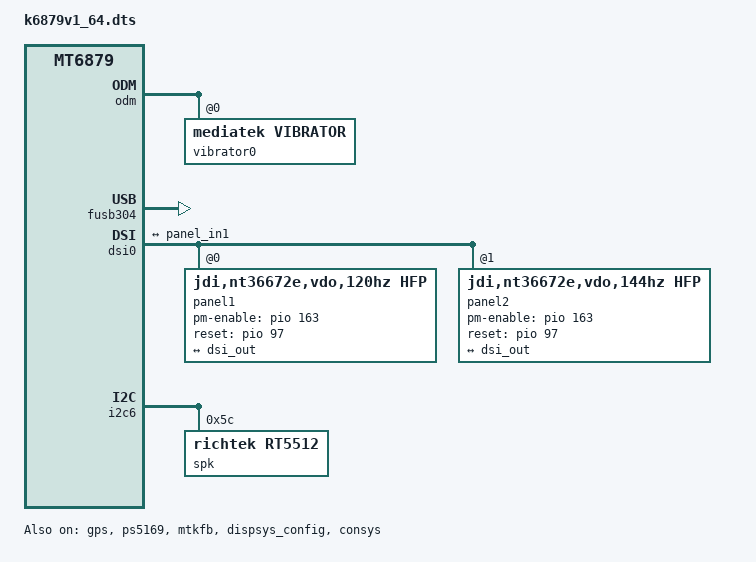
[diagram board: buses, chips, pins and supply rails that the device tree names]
// SPDX-License-Identifier: (GPL-2.0 OR MIT)
/*
 * Copyright (C) 2020 MediaTek Inc.
 * Author: Chun-Hung Wu <chun-hung.wu@mediatek.com>
 */
/dts-v1/;
/plugin/;
#include <dt-bindings/interrupt-controller/arm-gic.h>
#include <dt-bindings/interrupt-controller/irq.h>
#include <dt-bindings/pinctrl/mt6879-pinfunc.h>
#include <dt-bindings/phy/phy.h>
#include <dt-bindings/iio/mt635x-auxadc.h>

&chosen {
	bootargs_ext = "console=tty0 root=/dev/ram \
	androidboot.hardware=mt6879";
};

&mtk_leds {
	compatible = "mediatek,i2c-leds";
	backlight {
		led_mode = <6>;
		gate_enable = <1>;
		pwm_config = <0 1 0 0 0>;
	};
};

&odm {
	vibrator0:vibrator@0 {
		compatible = "mediatek,vibrator";
		vib_timer = <25>;
		vib_limit = <9>;
		vib_vol= <9>;
	};
};

/* GPS GPIO standardization start */
&pio {
	gps_pins_default: gps_default {
	};

	gps_l1_lna_pins_ol: gps_l1_lna@0 {
		pins_cmd_dat {
			pinmux = <PINMUX_GPIO23__FUNC_GPIO23>;
			output-low;
		};
	};
	gps_l1_lna_pins_dsp_ctrl: gps_l1_lna@1 {
		pins_cmd_dat {
			pinmux = <PINMUX_GPIO23__FUNC_GPS_L1_ELNA_EN>;
		};
	};
	gps_l1_lna_pins_oh: gps_l1_lna@2 {
		pins_cmd_dat {
			pinmux = <PINMUX_GPIO23__FUNC_GPIO23>;
			output-high;
		};
	};

	gps_l5_lna_pins_ol: gps_l5_lna@0 {
		pins_cmd_dat {
			pinmux = <PINMUX_GPIO26__FUNC_GPIO26>;
			output-low;
		};
	};
	gps_l5_lna_pins_dsp_ctrl: gps_l5_lna@1 {
		pins_cmd_dat {
			pinmux = <PINMUX_GPIO26__FUNC_GPS_L5_ELNA_EN>;
		};
	};
	gps_l5_lna_pins_oh: gps_l5_lna@2 {
		pins_cmd_dat {
			pinmux = <PINMUX_GPIO26__FUNC_GPIO26>;
			output-high;
		};
	};
};

&gps {
	pinctrl-names = "default",
		"gps_l1_lna_disable",
		"gps_l1_lna_dsp_ctrl",
		"gps_l1_lna_enable",
		"gps_l5_lna_disable",
		"gps_l5_lna_dsp_ctrl",
		"gps_l5_lna_enable";
	pinctrl-0 = <&gps_pins_default>;
	pinctrl-1 = <&gps_l1_lna_pins_ol>;
	pinctrl-2 = <&gps_l1_lna_pins_dsp_ctrl>;
	pinctrl-3 = <&gps_l1_lna_pins_oh>;
	pinctrl-4 = <&gps_l5_lna_pins_ol>;
	pinctrl-5 = <&gps_l5_lna_pins_dsp_ctrl>;
	pinctrl-6 = <&gps_l5_lna_pins_oh>;
	status = "okay";
};
/* GPS GPIO standardization end */

/* usb typec mux start */
&pio {
	sel_up: sel_high {
		pins_cmd_dat {
			pinmux = <PINMUX_GPIO60__FUNC_GPIO60>;
			output-high;
		};
	};

	sel_down: sel_low {
		pins_cmd_dat {
			pinmux = <PINMUX_GPIO60__FUNC_GPIO60>;
			output-low;
		};
	};

	sw_enable: sw_enable {
		pins_cmd_dat {
			pinmux = <PINMUX_GPIO59__FUNC_GPIO59>;
			output-low;
		};
	};

	sw_disable: sw_disable {
		pins_cmd_dat {
			pinmux = <PINMUX_GPIO59__FUNC_GPIO59>;
			output-low;
		};
	};

	ps_enable: ps_enable {
		pins_cmd_dat {
			pinmux = <PINMUX_GPIO136__FUNC_GPIO136>;
			output-high;
		};
	};

	ps_disable: ps_disable {
		pins_cmd_dat {
			pinmux = <PINMUX_GPIO136__FUNC_GPIO136>;
			output-low;
		};
	};
};

&ps5169{
	pinctrl-names = "enable", "disable";
	pinctrl-0 = <&ps_enable>;
	pinctrl-1 = <&ps_disable>;
	status = "okay";
};

&fusb304 {
	pinctrl-names = "sel_up", "sel_down",
		"enable", "disable";
	pinctrl-0 = <&sel_up>;
	pinctrl-1 = <&sel_down>;
	pinctrl-2 = <&sw_enable>;
	pinctrl-3 = <&sw_disable>;
	status = "okay";
};

&mt6375_typec {
	port {
		tcpc_typec_usb: endpoint@0 {
			remote-endpoint = <&ssusb_mux>;
		};
	};
};

&typec_mux_switch {
	orientation-switch;
	mode-switch;
	accessory;
	port {
		ssusb_mux: endpoint@0 {
			remote-endpoint = <&tcpc_typec_usb>;
		};
	};
};

/* usb typec mux end*/

&pio {
	mtkfb_pins_lcm_led_en1: lcm_led_en1_gpio {
		pins_cmd_dat {
			pinmux = <PINMUX_GPIO163__FUNC_GPIO163>;
			slew-rate = <1>;
			output-high;
		};
	};

	mtkfb_pins_lcm_led_en0: lcm_led_en0_gpio {
		pins_cmd_dat {
			pinmux = <PINMUX_GPIO163__FUNC_GPIO163>;
			slew-rate = <1>;
			output-low;
		};
	};

	mtkfb_pins_lcm_rst_out1_gpio: lcm_rst_out1_gpio {
		pins_cmd_dat {
			pinmux = <PINMUX_GPIO97__FUNC_GPIO97>;
			slew-rate = <1>;
			output-high;
		};
	};

	mtkfb_pins_lcm_rst_out0_gpio: lcm_rst_out0_gpio {
		pins_cmd_dat {
			pinmux = <PINMUX_GPIO97__FUNC_GPIO97>;
			slew-rate = <1>;
			output-low;
		};
	};

	mtkfb_pins_lcm_dsi_te: lcm_dsi_te {
		pins_cmd_dat {
			pinmux = <PINMUX_GPIO96__FUNC_DSI_TE>;
		};
	};
};

&mtkfb {
	pinctrl-names = "lcm_led_en1_gpio", "lcm_led_en0_gpio",
		"lcm_rst_out1_gpio", "lcm_rst_out0_gpio",
		"mode_te_te";
	pinctrl-0 = <&mtkfb_pins_lcm_led_en1>;
	pinctrl-1 = <&mtkfb_pins_lcm_led_en0>;
	pinctrl-2 = <&mtkfb_pins_lcm_rst_out1_gpio>;
	pinctrl-3 = <&mtkfb_pins_lcm_rst_out0_gpio>;
	pinctrl-4 = <&mtkfb_pins_lcm_dsi_te>;
	status = "okay";
};

&dispsys_config {
	pinctrl-names =
		"lcm_rst_out1_gpio", "lcm_rst_out0_gpio",
		"mode_te_te";
	pinctrl-0 = <&mtkfb_pins_lcm_rst_out1_gpio>;
	pinctrl-1 = <&mtkfb_pins_lcm_rst_out0_gpio>;
	pinctrl-2 = <&mtkfb_pins_lcm_dsi_te>;
	status = "okay";
};

&dsi0 {
	status = "okay";
	#address-cells = <1>;
	#size-cells = <0>;
	switch_fps = <144>;
	panel1@0 {
		compatible = "jdi,nt36672e,vdo,120hz,hfp";
		reg = <0>;
		pm-enable-gpios = <&pio 163 0>;
		reset-gpios = <&pio 97 0>;
		gate-ic = <4831>;
		pinctrl-names = "default";
		port {
			panel_in1: endpoint {
				remote-endpoint = <&dsi_out>;
			};
		};
	};

	panel2@0 {
		compatible = "jdi,nt36672e,vdo,144hz,hfp";
		reg = <1>;
		pm-enable-gpios = <&pio 163 0>;
		reset-gpios = <&pio 97 0>;
		gate-ic = <4831>;
		pinctrl-names = "default";
		port {
			panel_in2: endpoint {
				remote-endpoint = <&dsi_out>;
			};
		};
	};

	ports {
		port {
			dsi_out: endpoint {
				remote-endpoint = <&panel_in1>;
			};
		};
	};
};

&connfem {
#if 0 /* Enable epa_elna node to support Wifi & BT ePA/eLNA FEM on customer load */
	epa_elna {
		parts = <&qm42195 &qm45197>;

		wifi {
			flags-0 {
				open-loop;
			};
		};

		bt {
			flags-0 {
				/* choose one of: epa_elna / epa / elna / bypass */
				epa_elna;
			};
		};
	};
#endif

	epa_elna_mtk {
		parts = <&nofem &nofem>,		/* [0]iPA/iLNA */
			<&qm42195 &qm45197>,		/* [1]ePA/eLNA - close Loop */
			<&nofem &wlan3002c_laa>,	/* [2]2.4G iPA/iLNA, 5G iPA/eLNA, LAA 4x4 */
			<&qm42195 &qm45197_laa>,	/* [3]ePA/eLNA - close Loop, LAA 4x4 */
			<&qm42195 &qm45197>,		/* [4]ePA/eLNA - open Loop */
			<&qm42195 &qm45197>,		/* [5]ePA/eLNA - close Loop + BT Bypass */
			<&qm42195 &qm45197>,		/* [6]ePA/eLNA - open Loop + BT Bypass */
			<&wlan7207h &wlan7205c>,	/* [7]ePA/eLNA - close Loop */
			<&wlan7207h &wlan7205c>;	/* [8]ePA/eLNA - open Loop */

		hwid {
			gpio = <&pio 125 0x0>;
			pmic {
				channel_name = "pmic_vin1";
				range-0 = <320>;
			};
		};

		wifi {
			flags-2 {
				laa;
			};
			flags-3 {
				laa;
			};
			flags-4 {
				open-loop;
			};
			flags-6 {
				open-loop;
			};
			flags-8 {
				open-loop;
			};
		};

		bt {
			flags-1 {
				/* choose one of: epa_elna / epa / elna / bypass */
				epa_elna;
			};
			flags-3 {
				/* choose one of: epa_elna / epa / elna / bypass */
				epa_elna;
			};
			flags-4 {
				/* choose one of: epa_elna / epa / elna / bypass */
				epa_elna;
			};
			flags-5 {
				/* choose one of: epa_elna / epa / elna / bypass */
				bypass;
			};
			flags-6 {
				/* choose one of: epa_elna / epa / elna / bypass */
				bypass;
			};
			flags-7 {
				/* choose one of: epa_elna / epa / elna / bypass */
				epa_elna;
			};
			flags-8 {
				/* choose one of: epa_elna / epa / elna / bypass */
				epa_elna;
			};
		};
	};
};

#include <k6879v1_64/cust.dtsi>

&i2c6 {
	spk: speaker_amp@5c {
		compatible = "richtek,rt5512";
		#sound-dai-cells = <0>;
		reg = <0x5c>;
		status = "okay";
		sound-name-prefix = "Left";
	};
};

&sound {
	mediatek,spk-i2s = <1 2>;
	mediatek,speaker-codec {
		sound-dai = <&spk>;
	};
};

/* AUDIO GPIO standardization start */
&afe {
	pinctrl-names = "aud_clk_mosi_off",
			"aud_clk_mosi_on",
			"aud_dat_mosi_off",
			"aud_dat_mosi_on",
			"aud_dat_mosi_ch34_off",
			"aud_dat_mosi_ch34_on",
			"aud_dat_miso0_off",
			"aud_dat_miso0_on",
			"aud_dat_miso1_off",
			"aud_dat_miso1_on",
			"aud_dat_miso2_off",
			"aud_dat_miso2_on",
			"vow_dat_miso_off",
			"vow_dat_miso_on",
			"vow_clk_miso_off",
			"vow_clk_miso_on",
			"aud_gpio_i2s2_off",
			"aud_gpio_i2s2_on",
			"aud_gpio_i2s1_off",
			"aud_gpio_i2s1_on";
	pinctrl-0 = <&aud_clk_mosi_off>;
	pinctrl-1 = <&aud_clk_mosi_on>;
	pinctrl-2 = <&aud_dat_mosi_off>;
	pinctrl-3 = <&aud_dat_mosi_on>;
	pinctrl-4 = <&aud_dat_mosi_ch34_off>;
	pinctrl-5 = <&aud_dat_mosi_ch34_on>;
	pinctrl-6 = <&aud_dat_miso0_off>;
	pinctrl-7 = <&aud_dat_miso0_on>;
	pinctrl-8 = <&aud_dat_miso1_off>;
	pinctrl-9 = <&aud_dat_miso1_on>;
	pinctrl-10 = <&aud_dat_miso2_off>;
	pinctrl-11 = <&aud_dat_miso2_on>;
	pinctrl-12 = <&vow_dat_miso_off>;
	pinctrl-13 = <&vow_dat_miso_on>;
	pinctrl-14 = <&vow_clk_miso_off>;
	pinctrl-15 = <&vow_clk_miso_on>;
	pinctrl-16 = <&aud_gpio_i2s2_off>;
	pinctrl-17 = <&aud_gpio_i2s2_on>;
	pinctrl-18 = <&aud_gpio_i2s1_off>;
	pinctrl-19 = <&aud_gpio_i2s1_on>;
};
&pio {
	aud_clk_mosi_off: aud_clk_mosi_off {
		pins_cmd0_dat {
			pinmux = <PINMUX_GPIO178__FUNC_GPIO178>;
			input-enable;
			bias-pull-down;
		};
	};
	aud_clk_mosi_on: aud_clk_mosi_on {
		pins_cmd0_dat {
			pinmux = <PINMUX_GPIO178__FUNC_AUD_CLK_MOSI>;
			input-schmitt-enable;
			bias-disable;
		};
	};
	aud_dat_mosi_off: aud_dat_mosi_off {
		pins_cmd1_dat {
			pinmux = <PINMUX_GPIO180__FUNC_GPIO180>;
			input-enable;
			bias-pull-down;
		};
	};
	aud_dat_mosi_on: aud_dat_mosi_on {
		pins_cmd1_dat {
			pinmux = <PINMUX_GPIO180__FUNC_AUD_DAT_MOSI0>;
			input-schmitt-enable;
			bias-disable;
		};
	};
	aud_dat_mosi_ch34_off: aud_dat_mosi_ch34_off {
		pins_cmd1_dat {
			pinmux = <PINMUX_GPIO181__FUNC_GPIO181>;
			input-enable;
			bias-pull-down;
		};
	};
	aud_dat_mosi_ch34_on: aud_dat_mosi_ch34_on {
		pins_cmd1_dat {
			pinmux = <PINMUX_GPIO181__FUNC_AUD_DAT_MOSI1>;
			input-schmitt-enable;
			bias-disable;
		};
	};
	aud_dat_miso0_off: aud_dat_miso0_off {
		pins_cmd1_dat {
			pinmux = <PINMUX_GPIO185__FUNC_GPIO185>;
			input-enable;
			bias-pull-down;
		};
	};
	aud_dat_miso0_on: aud_dat_miso0_on {
		pins_cmd1_dat {
			pinmux = <PINMUX_GPIO185__FUNC_AUD_DAT_MISO0>;
			input-schmitt-enable;
			bias-disable;
		};
	};
	aud_dat_miso1_off: aud_dat_miso1_off {
		pins_cmd2_dat {
			pinmux = <PINMUX_GPIO186__FUNC_GPIO186>;
			input-enable;
			bias-disable;
		};
	};
	aud_dat_miso1_on: aud_dat_miso1_on {
		pins_cmd2_dat {
			pinmux = <PINMUX_GPIO186__FUNC_AUD_DAT_MISO1>;
			input-schmitt-enable;
			bias-disable;
		};
	};
	aud_dat_miso2_off: aud_dat_miso2_off {
		pins_cmd1_dat {
			pinmux = <PINMUX_GPIO187__FUNC_GPIO187>;
			input-enable;
			bias-pull-down;
		};
	};
	aud_dat_miso2_on: aud_dat_miso2_on {
		pins_cmd1_dat {
			pinmux = <PINMUX_GPIO187__FUNC_AUD_DAT_MISO2>;
			input-schmitt-enable;
			bias-disable;
		};
	};
	vow_dat_miso_off: vow_dat_miso_off {
		pins_cmd1_dat {
			pinmux = <PINMUX_GPIO185__FUNC_GPIO185>;
			input-enable;
			bias-pull-down;
		};
	};
	vow_dat_miso_on: vow_dat_miso_on {
		pins_cmd1_dat {
			pinmux = <PINMUX_GPIO185__FUNC_VOW_DAT_MISO>;
			input-schmitt-enable;
			bias-disable;
		};
	};
	vow_clk_miso_off: vow_clk_miso_off {
		pins_cmd3_dat {
			pinmux = <PINMUX_GPIO186__FUNC_GPIO186>;
			input-enable;
			bias-pull-down;
		};
	};
	vow_clk_miso_on: vow_clk_miso_on {
		pins_cmd1_dat {
			pinmux = <PINMUX_GPIO186__FUNC_VOW_CLK_MISO>;
			input-schmitt-enable;
			bias-disable;
		};
	};
	aud_nle_mosi_off: aud_nle_mosi_off {
		pins_cmd1_dat {
			pinmux = <PINMUX_GPIO183__FUNC_GPIO183>;
			input-enable;
			bias-pull-down;
		};
		pins_cmd2_dat {
			pinmux = <PINMUX_GPIO184__FUNC_GPIO184>;
			input-enable;
			bias-pull-down;
		};
	};
	aud_nle_mosi_on: aud_nle_mosi_on {
		pins_cmd1_dat {
			pinmux = <PINMUX_GPIO183__FUNC_AUD_NLE_MOSI0>;
			input-schmitt-enable;
			bias-disable;
		};
		pins_cmd2_dat {
			pinmux = <PINMUX_GPIO184__FUNC_AUD_NLE_MOSI1>;
			input-schmitt-enable;
			bias-disable;
		};
	};
	aud_gpio_i2s2_off: aud_gpio_i2s2_off {
		pins_cmd1_dat {
			pinmux = <PINMUX_GPIO39__FUNC_GPIO39>;
			input-enable;
			bias-pull-down;
		};
	};
	aud_gpio_i2s2_on: aud_gpio_i2s2_on {
		pins_cmd1_dat {
			pinmux = <PINMUX_GPIO39__FUNC_I2S2_DI>;
			input-schmitt-enable;
			bias-disable;
		};
	};
	aud_gpio_i2s1_off: aud_gpio_i2s1_off {
		pins_cmd1_dat {
			pinmux = <PINMUX_GPIO36__FUNC_GPIO36>;
			input-enable;
			bias-pull-down;
		};
		pins_cmd2_dat {
			pinmux = <PINMUX_GPIO37__FUNC_GPIO37>;
			input-enable;
			bias-pull-down;
		};
		pins_cmd3_dat {
			pinmux = <PINMUX_GPIO38__FUNC_GPIO38>;
			input-enable;
			bias-pull-down;
		};
	};
	aud_gpio_i2s1_on: aud_gpio_i2s1_on {
		pins_cmd1_dat {
			pinmux = <PINMUX_GPIO36__FUNC_I2S1_BCK>;
			input-schmitt-enable;
			bias-disable;
		};
		pins_cmd2_dat {
			pinmux = <PINMUX_GPIO37__FUNC_I2S1_LRCK>;
			input-schmitt-enable;
			bias-disable;
		};
		pins_cmd3_dat {
			pinmux = <PINMUX_GPIO38__FUNC_I2S1_DO>;
			input-schmitt-enable;
			bias-disable;
		};
	};
};
/* AUDIO GPIO standardization end */

/* CONNSYS TCXO GPIO start */
&consys {
	tcxo_support = "false";
	pinctrl-names = "default", "conninfra_tcxo_set", "conninfra_tcxo_clr";
	pinctrl-0 = <&conninfra_pins_default>;
	pinctrl-1 = <&conninfra_pins_tcxo_set>;
	pinctrl-2 = <&conninfra_pins_tcxo_clr>;
	status = "okay";
};

&pio {
	conninfra_pins_default: conninfra_pins_default {
	};
	conninfra_pins_tcxo_set: conninfra_tcxo_set@gpio {
		pins_cmd_dat {
			pinmux = <PINMUX_GPIO168__FUNC_CONN_TCXOENA_REQ>;
		};
	};
	conninfra_pins_tcxo_clr: conninfra_tcxo_clr@gpio {
		pins_cmd_dat {
			pinmux = <PINMUX_GPIO168__FUNC_GPIO168>;
		};
	};
};
/* CONNSYS TCXO GPIO end */

&pdc {
	pd_vbus_upper_bound = <12000000>;
};

#include "mediatek/cust_mt6879_touch_1080x2400.dtsi"
#include "mediatek/cust_mt6879_camera_v4l2.dtsi"
/*End of this file, DO NOT ADD ANYTHING HERE*/
